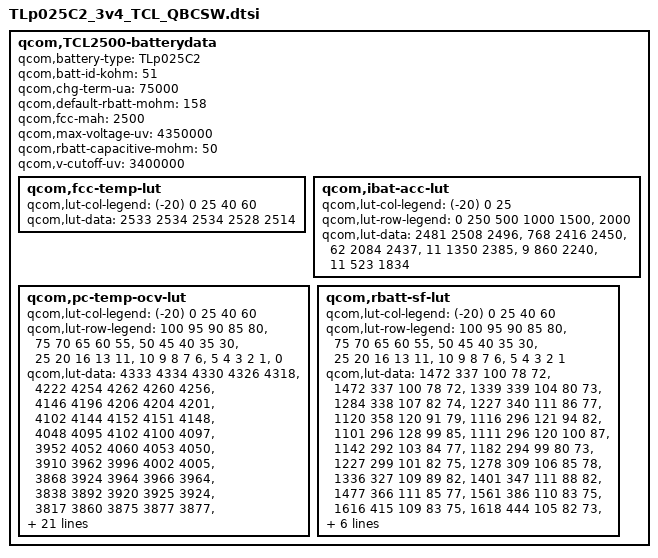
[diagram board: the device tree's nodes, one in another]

qcom,TCL2500-batterydata {
	qcom,battery-type = "TLp025C2";
	qcom,batt-id-kohm = <51>;
	qcom,chg-term-ua = <75000>;
	qcom,default-rbatt-mohm = <158>;
	qcom,fcc-mah = <2500>;
	qcom,max-voltage-uv = <4350000>;
	qcom,rbatt-capacitive-mohm = <50>;
	qcom,v-cutoff-uv = <3400000>;

	qcom,fcc-temp-lut {
		qcom,lut-col-legend = <(-20) 0 25 40 60>;
		qcom,lut-data = <2533 2534 2534 2528 2514>;
	};

	qcom,ibat-acc-lut {
		qcom,lut-col-legend = <(-20) 0 25>;
		qcom,lut-row-legend = <0 250 500 1000 1500>,
					<2000>;
		qcom,lut-data = <2481 2508 2496>,
				<768 2416 2450>,
				<62 2084 2437>,
				<11 1350 2385>,
				<9 860 2240>,
				<11 523 1834>;
	};

	qcom,pc-temp-ocv-lut {
		qcom,lut-col-legend = <(-20) 0 25 40 60>;
		qcom,lut-row-legend = <100 95 90 85 80>,
					<75 70 65 60 55>,
					<50 45 40 35 30>,
					<25 20 16 13 11>,
					<10 9 8 7 6>,
					<5 4 3 2 1>,
					<0>;
		qcom,lut-data = <4333 4334 4330 4326 4318>,
				<4222 4254 4262 4260 4256>,
				<4146 4196 4206 4204 4201>,
				<4102 4144 4152 4151 4148>,
				<4048 4095 4102 4100 4097>,
				<3952 4052 4060 4053 4050>,
				<3910 3962 3996 4002 4005>,
				<3868 3924 3964 3966 3964>,
				<3838 3892 3920 3925 3924>,
				<3817 3860 3875 3877 3877>,
				<3801 3832 3844 3845 3845>,
				<3786 3809 3820 3822 3822>,
				<3772 3791 3802 3802 3802>,
				<3756 3778 3786 3786 3785>,
				<3742 3766 3772 3770 3766>,
				<3724 3750 3758 3752 3740>,
				<3707 3730 3740 3731 3718>,
				<3689 3716 3717 3708 3694>,
				<3672 3708 3696 3688 3674>,
				<3660 3702 3690 3682 3670>,
				<3652 3698 3689 3681 3669>,
				<3644 3694 3688 3680 3668>,
				<3634 3690 3686 3679 3667>,
				<3620 3684 3684 3676 3663>,
				<3604 3676 3676 3668 3650>,
				<3584 3656 3654 3642 3620>,
				<3556 3621 3610 3596 3572>,
				<3516 3566 3548 3534 3508>,
				<3454 3486 3462 3448 3421>,
				<3330 3356 3326 3316 3284>,
				<3000 3000 3000 3000 3000>;
	};

	qcom,rbatt-sf-lut {
		qcom,lut-col-legend = <(-20) 0 25 40 60>;
		qcom,lut-row-legend = <100 95 90 85 80>,
					<75 70 65 60 55>,
					<50 45 40 35 30>,
					<25 20 16 13 11>,
					<10 9 8 7 6>,
					<5 4 3 2 1>;
		qcom,lut-data = <1472 337 100 78 72>,
				<1472 337 100 78 72>,
				<1339 339 104 80 73>,
				<1284 338 107 82 74>,
				<1227 340 111 86 77>,
				<1120 358 120 91 79>,
				<1116 296 121 94 82>,
				<1101 296 128 99 85>,
				<1111 296 120 100 87>,
				<1142 292 103 84 77>,
				<1182 294 99 80 73>,
				<1227 299 101 82 75>,
				<1278 309 106 85 78>,
				<1336 327 109 89 82>,
				<1401 347 111 88 82>,
				<1477 366 111 85 77>,
				<1561 386 110 83 75>,
				<1616 415 109 83 75>,
				<1618 444 105 82 73>,
				<1489 432 104 82 75>,
				<1522 444 107 84 76>,
				<1554 457 111 86 77>,
				<1587 475 116 89 78>,
				<1650 495 120 92 80>,
				<1800 514 123 92 78>,
				<1984 526 119 87 76>,
				<2230 539 116 86 76>,
				<2571 563 120 88 78>,
				<3126 605 127 93 84>,
				<5201 718 177 123 113>;
	};
};
/* TEST_DB_ID=TEST_ID_NOT_SET */
